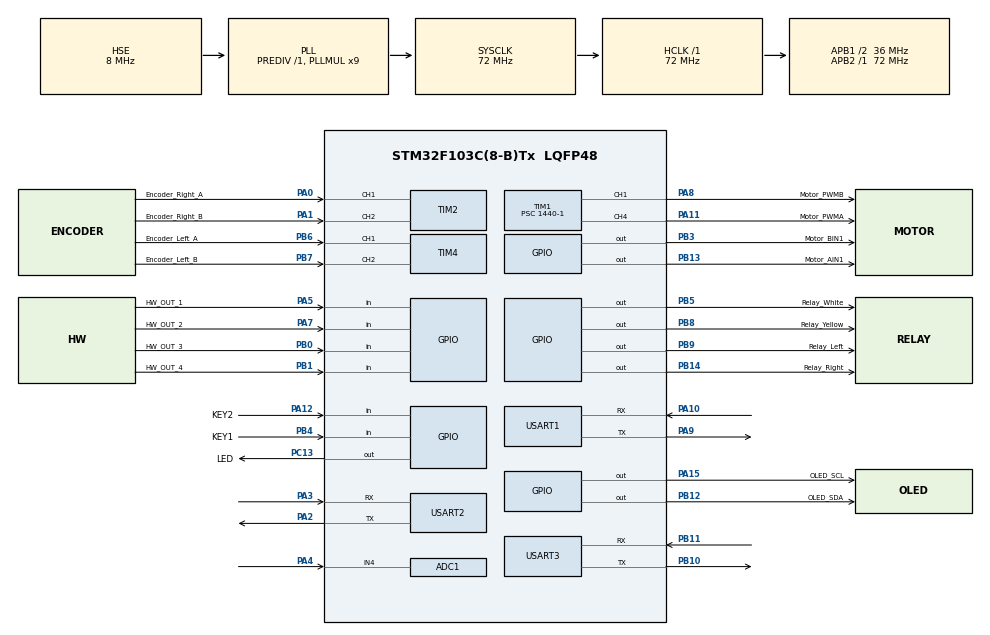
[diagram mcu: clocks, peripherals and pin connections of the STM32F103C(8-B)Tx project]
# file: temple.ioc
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ADC1.Channel-0\#ChannelRegularConversion=ADC_CHANNEL_4
ADC1.NbrOfConversionFlag=1
ADC1.Rank-0\#ChannelRegularConversion=1
ADC1.SamplingTime-0\#ChannelRegularConversion=ADC_SAMPLETIME_1CYCLE_5
ADC1.master=1
Dma.ADC1.2.Direction=DMA_PERIPH_TO_MEMORY
Dma.ADC1.2.Instance=DMA1_Channel1
Dma.ADC1.2.MemDataAlignment=DMA_MDATAALIGN_HALFWORD
Dma.ADC1.2.MemInc=DMA_MINC_ENABLE
Dma.ADC1.2.Mode=DMA_CIRCULAR
Dma.ADC1.2.PeriphDataAlignment=DMA_PDATAALIGN_HALFWORD
Dma.ADC1.2.PeriphInc=DMA_PINC_DISABLE
Dma.ADC1.2.Priority=DMA_PRIORITY_LOW
Dma.Request0=USART1_RX
Dma.Request1=USART3_RX
Dma.Request2=ADC1
Dma.Request3=USART2_RX
Dma.USART1_RX.0.Direction=DMA_PERIPH_TO_MEMORY
Dma.USART1_RX.0.Instance=DMA1_Channel5
Dma.USART1_RX.0.MemDataAlignment=DMA_MDATAALIGN_BYTE
Dma.USART1_RX.0.MemInc=DMA_MINC_ENABLE
Dma.USART1_RX.0.Mode=DMA_CIRCULAR
Dma.USART1_RX.0.PeriphDataAlignment=DMA_PDATAALIGN_BYTE
Dma.USART1_RX.0.PeriphInc=DMA_PINC_DISABLE
Dma.USART1_RX.0.Priority=DMA_PRIORITY_LOW
Dma.USART2_RX.3.Direction=DMA_PERIPH_TO_MEMORY
Dma.USART2_RX.3.Instance=DMA1_Channel6
Dma.USART2_RX.3.MemDataAlignment=DMA_MDATAALIGN_HALFWORD
Dma.USART2_RX.3.MemInc=DMA_MINC_ENABLE
Dma.USART2_RX.3.Mode=DMA_CIRCULAR
Dma.USART2_RX.3.PeriphDataAlignment=DMA_PDATAALIGN_HALFWORD
Dma.USART2_RX.3.PeriphInc=DMA_PINC_DISABLE
Dma.USART2_RX.3.Priority=DMA_PRIORITY_LOW
Dma.USART3_RX.1.Direction=DMA_PERIPH_TO_MEMORY
Dma.USART3_RX.1.Instance=DMA1_Channel3
Dma.USART3_RX.1.MemDataAlignment=DMA_MDATAALIGN_BYTE
Dma.USART3_RX.1.MemInc=DMA_MINC_ENABLE
Dma.USART3_RX.1.Mode=DMA_CIRCULAR
Dma.USART3_RX.1.PeriphDataAlignment=DMA_PDATAALIGN_BYTE
Dma.USART3_RX.1.PeriphInc=DMA_PINC_DISABLE
Dma.USART3_RX.1.Priority=DMA_PRIORITY_LOW
Mcu.Family=STM32F1
Mcu.Name=STM32F103C(8-B)Tx
Mcu.Package=LQFP48
NVIC.DMA1_Channel1_IRQn=true\:0\:0\:false\:false\:true\:false\:true\:true
NVIC.DMA1_Channel3_IRQn=true\:0\:0\:false\:false\:true\:false\:true\:true
NVIC.DMA1_Channel5_IRQn=true\:0\:0\:false\:false\:true\:false\:true\:true
NVIC.DMA1_Channel6_IRQn=true\:0\:0\:false\:false\:true\:false\:true\:true
NVIC.PriorityGroup=NVIC_PRIORITYGROUP_4
NVIC.TIM1_UP_IRQn=true\:0\:0\:false\:false\:true\:true\:true\:true
NVIC.TIM2_IRQn=true\:0\:0\:false\:false\:true\:true\:true\:true
NVIC.TIM4_IRQn=true\:0\:0\:false\:false\:true\:true\:true\:true
NVIC.USART1_IRQn=true\:0\:0\:false\:false\:true\:true\:true\:true
NVIC.USART2_IRQn=true\:0\:0\:false\:false\:true\:true\:true\:true
NVIC.USART3_IRQn=true\:0\:0\:false\:false\:true\:true\:true\:true
PA0-WKUP.GPIO_Label=Encoder_Right_A
PA0-WKUP.GPIO_PuPd=GPIO_PULLUP
PA0-WKUP.Signal=S_TIM2_CH1_ETR
PA1.GPIO_Label=Encoder_Right_B
PA1.GPIO_PuPd=GPIO_PULLUP
PA1.Signal=S_TIM2_CH2
PA10.Mode=Asynchronous
PA10.Signal=USART1_RX
PA11.GPIO_Label=Motor_PWMA
PA11.Signal=S_TIM1_CH4
PA12.GPIO_Label=KEY2
PA12.GPIO_PuPd=GPIO_PULLUP
PA12.Signal=GPIO_Input
PA13.Mode=Serial_Wire
PA13.Signal=SYS_JTMS-SWDIO
PA14.Mode=Serial_Wire
PA14.Signal=SYS_JTCK-SWCLK
PA15.GPIO_Label=OLED_SCL
PA15.GPIO_Speed=GPIO_SPEED_FREQ_MEDIUM
PA15.PinState=GPIO_PIN_SET
PA15.Signal=GPIO_Output
PA2.Mode=Asynchronous
PA2.Signal=USART2_TX
PA3.Mode=Asynchronous
PA3.Signal=USART2_RX
PA4.Signal=ADCx_IN4
PA5.GPIO_Label=HW_OUT_1
PA5.Signal=GPIO_Input
PA7.GPIO_Label=HW_OUT_2
PA7.Signal=GPIO_Input
PA8.GPIO_Label=Motor_PWMB
PA8.Signal=S_TIM1_CH1
PA9.Mode=Asynchronous
PA9.Signal=USART1_TX
PB0.GPIO_Label=HW_OUT_3
PB0.Signal=GPIO_Input
PB1.GPIO_Label=HW_OUT_4
PB1.Signal=GPIO_Input
PB10.Mode=Asynchronous
PB10.Signal=USART3_TX
PB11.Mode=Asynchronous
PB11.Signal=USART3_RX
PB12.GPIO_Label=OLED_SDA
PB12.GPIO_Speed=GPIO_SPEED_FREQ_MEDIUM
PB12.PinState=GPIO_PIN_SET
PB12.Signal=GPIO_Output
PB13.GPIO_Label=Motor_AIN1
PB13.Signal=GPIO_Output
PB14.GPIO_Label=Relay_Right
PB14.Signal=GPIO_Output
PB3.GPIO_Label=Motor_BIN1
PB3.Signal=GPIO_Output
PB4.GPIO_Label=KEY1
PB4.GPIO_PuPd=GPIO_PULLDOWN
PB4.Signal=GPIO_Input
PB5.GPIO_Label=Relay_White
PB5.Signal=GPIO_Output
PB6.GPIO_Label=Encoder_Left_A
PB6.GPIO_PuPd=GPIO_PULLUP
PB6.Signal=S_TIM4_CH1
PB7.GPIO_Label=Encoder_Left_B
PB7.GPIO_PuPd=GPIO_PULLUP
PB7.Signal=S_TIM4_CH2
PB8.GPIO_Label=Relay_Yellow
PB8.Signal=GPIO_Output
PB9.GPIO_Label=Relay_Left
PB9.Signal=GPIO_Output
PC13-TAMPER-RTC.GPIO_Label=LED
PC13-TAMPER-RTC.Signal=GPIO_Output
PD0-OSC_IN.Mode=HSE-External-Oscillator
PD0-OSC_IN.Signal=RCC_OSC_IN
PD1-OSC_OUT.Mode=HSE-External-Oscillator
PD1-OSC_OUT.Signal=RCC_OSC_OUT
ProjectManager.HeapSize=0x200
ProjectManager.StackSize=0x400
ProjectManager.TargetToolchain=MDK-ARM V5.32
RCC.ADCPresc=RCC_ADCPCLK2_DIV6
RCC.AHBFreq_Value=72000000
RCC.APB1CLKDivider=RCC_HCLK_DIV2
RCC.APB1Freq_Value=36000000
RCC.APB1TimFreq_Value=72000000
RCC.APB2Freq_Value=72000000
RCC.APB2TimFreq_Value=72000000
RCC.HCLKFreq_Value=72000000
RCC.PLLMUL=RCC_PLL_MUL9
RCC.PLLSourceVirtual=RCC_PLLSOURCE_HSE
RCC.SYSCLKFreq_VALUE=72000000
RCC.SYSCLKSource=RCC_SYSCLKSOURCE_PLLCLK
RCC.USBFreq_Value=72000000
SH.ADCx_IN4.0=ADC1_IN4,IN4
SH.S_TIM1_CH1.0=TIM1_CH1,PWM Generation1 CH1
SH.S_TIM1_CH4.0=TIM1_CH4,PWM Generation4 CH4
SH.S_TIM2_CH1_ETR.0=TIM2_CH1,Encoder_Interface
SH.S_TIM2_CH2.0=TIM2_CH2,Encoder_Interface
SH.S_TIM4_CH1.0=TIM4_CH1,Encoder_Interface
SH.S_TIM4_CH2.0=TIM4_CH2,Encoder_Interface
TIM1.Channel-PWM\ Generation1\ CH1=TIM_CHANNEL_1
TIM1.Channel-PWM\ Generation4\ CH4=TIM_CHANNEL_4
TIM1.Period=100-1
TIM1.Prescaler=1440-1
TIM2.EncoderMode=TIM_ENCODERMODE_TI12
TIM2.IC1Filter=6
TIM2.IC2Filter=6
TIM4.EncoderMode=TIM_ENCODERMODE_TI12
TIM4.IC1Filter=6
TIM4.IC2Filter=6
USART1.VirtualMode=VM_ASYNC
USART2.VirtualMode=VM_ASYNC
USART3.VirtualMode=VM_ASYNC
VP_TIM1_VS_ClockSourceINT.Mode=Internal
board=custom

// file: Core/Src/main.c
/* USER CODE BEGIN Header */
/**
  ******************************************************************************
  * @file           : main.c
  * @brief          : Main program body
  ******************************************************************************
  * @attention
  *
  * Copyright (c) 2023 STMicroelectronics.
  * All rights reserved.
  *
  * This software is licensed under terms that can be found in the LICENSE file
  * in the root directory of this software component.
  * If no LICENSE file comes with this software, it is provided AS-IS.
  *
  ******************************************************************************
  */
/* USER CODE END Header */
#include "main.h"
#include "adc.h"
#include "dma.h"
#include "tim.h"
#include "usart.h"
#include "gpio.h"

/* USER CODE BEGIN Includes */
#include "AllHead.h"

/* USER CODE END Includes */

void SystemClock_Config(void);

int main(void)
{

  /* MCU Configuration--------------------------------------------------------*/

  /* Reset of all peripherals, Initializes the Flash interface and the Systick. */
  HAL_Init();

  /* Configure the system clock */
  SystemClock_Config();

  /* Initialize all configured peripherals */
  MX_GPIO_Init();
  MX_DMA_Init();
  MX_TIM1_Init();
  MX_TIM2_Init();
  MX_TIM4_Init();
  MX_USART1_UART_Init();
  MX_USART3_UART_Init();
  MX_ADC1_Init();
  MX_USART2_UART_Init();
  /* USER CODE BEGIN 2 */
  System_Init.Hardware_Init();  // 硬件初始�??
  /* USER CODE END 2 */

  /* Infinite loop */
  /* USER CODE BEGIN WHILE */
  while (1)
  {
    System.System_Run();  // 系统运行
    /* USER CODE END WHILE */

  }
}

void SystemClock_Config(void)
{
  RCC_OscInitTypeDef RCC_OscInitStruct = {0};
  RCC_ClkInitTypeDef RCC_ClkInitStruct = {0};
  RCC_PeriphCLKInitTypeDef PeriphClkInit = {0};

  /** Initializes the RCC Oscillators according to the specified parameters
  * in the RCC_OscInitTypeDef structure.
  */
  RCC_OscInitStruct.OscillatorType = RCC_OSCILLATORTYPE_HSE;
  RCC_OscInitStruct.HSEState = RCC_HSE_ON;
  RCC_OscInitStruct.HSEPredivValue = RCC_HSE_PREDIV_DIV1;
  RCC_OscInitStruct.HSIState = RCC_HSI_ON;
  RCC_OscInitStruct.PLL.PLLState = RCC_PLL_ON;
  RCC_OscInitStruct.PLL.PLLSource = RCC_PLLSOURCE_HSE;
  RCC_OscInitStruct.PLL.PLLMUL = RCC_PLL_MUL9;
  if (HAL_RCC_OscConfig(&RCC_OscInitStruct) != HAL_OK)
  {
    Error_Handler();
  }

  /** Initializes the CPU, AHB and APB buses clocks
  */
  RCC_ClkInitStruct.ClockType = RCC_CLOCKTYPE_HCLK|RCC_CLOCKTYPE_SYSCLK
                              |RCC_CLOCKTYPE_PCLK1|RCC_CLOCKTYPE_PCLK2;
  RCC_ClkInitStruct.SYSCLKSource = RCC_SYSCLKSOURCE_PLLCLK;
  RCC_ClkInitStruct.AHBCLKDivider = RCC_SYSCLK_DIV1;
  RCC_ClkInitStruct.APB1CLKDivider = RCC_HCLK_DIV2;
  RCC_ClkInitStruct.APB2CLKDivider = RCC_HCLK_DIV1;

  if (HAL_RCC_ClockConfig(&RCC_ClkInitStruct, FLASH_LATENCY_2) != HAL_OK)
  {
    Error_Handler();
  }
  PeriphClkInit.PeriphClockSelection = RCC_PERIPHCLK_ADC;
  PeriphClkInit.AdcClockSelection = RCC_ADCPCLK2_DIV6;
  if (HAL_RCCEx_PeriphCLKConfig(&PeriphClkInit) != HAL_OK)
  {
    Error_Handler();
  }
}

void Error_Handler(void)
{
  __disable_irq();
  while (1)
  {
  }
}
